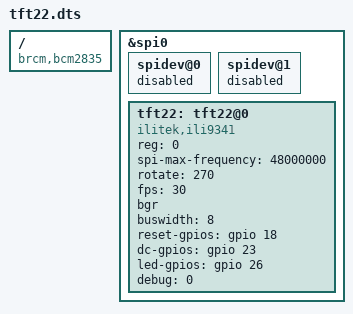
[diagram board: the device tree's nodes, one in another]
/dts-v1/;
/plugin/;

/ {
    compatible = "brcm,bcm2835", "brcm,bcm2708", "brcm,bcm2709";

    fragment@0 {
        target = <&spi0>;
        __overlay__ {
            status = "okay";

            spidev@0{
                status = "disabled";
            };

            spidev@1{
                status = "disabled";
            };
        };
    };

    fragment@1 {
        target = <&spi0>;
        __overlay__ {
            /* needed to avoid dtc warning */
            #address-cells = <1>;
            #size-cells = <0>;

            tft22: tft22@0 {
                compatible = "ilitek,ili9341";
                reg = <0>;
                pinctrl-names = "default";

                spi-max-frequency = <48000000>;
                rotate = <270>;
                fps = <30>;
                bgr;
                buswidth = <8>;

                reset-gpios = <&gpio 18 0>;
                dc-gpios = <&gpio 23 0>;
                led-gpios = <&gpio 26 0>;
                debug = <0>;

            };
        };
    };

    __overrides__ {
        speed = <&tft22>,"spi-max-frequency:0";
        rotate = <&tft22>,"rotate:0";
        fps = <&tft22>,"fps:0";
        debug = <&tft22>,"debug:0";
    };
};
